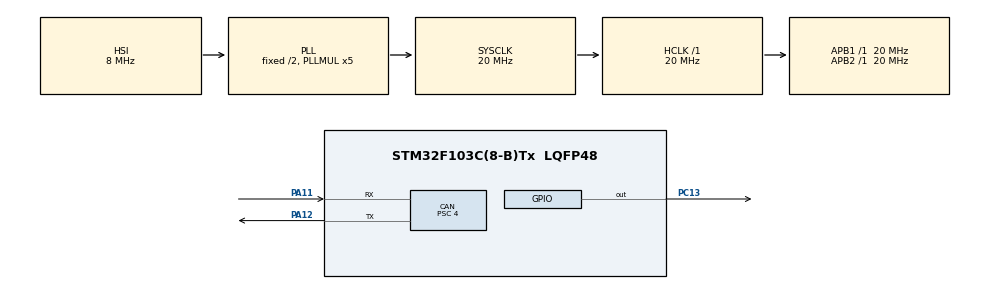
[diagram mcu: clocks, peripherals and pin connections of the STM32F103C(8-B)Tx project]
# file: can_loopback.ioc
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Mcu.Family=STM32F1
PD1-OSC_OUT.Mode=HSE-External-Oscillator
CAN.CalculateBaudRate=500000
PC13-TAMPER-RTC.Signal=GPIO_Output
PA11.Mode=CAN_Activate
PD0-OSC_IN.Signal=RCC_OSC_IN
CAN.CalculateTimeBit=2000.00
RCC.SYSCLKSource=RCC_SYSCLKSOURCE_PLLCLK
ProjectManager.StackSize=0x400
PD1-OSC_OUT.Signal=RCC_OSC_OUT
PA13.Signal=SYS_JTMS-SWDIO
PA12.Signal=CAN_TX
CAN.Prescaler=4
CAN.BS1=CAN_BS1_8TQ
ProjectManager.TargetToolchain=STM32CubeIDE
RCC.HCLKFreq_Value=20000000
RCC.APB2TimFreq_Value=20000000
RCC.USBFreq_Value=20000000
CAN.Mode=CAN_MODE_LOOPBACK
RCC.AHBFreq_Value=20000000
PD0-OSC_IN.Mode=HSE-External-Oscillator
board=custom
RCC.PLLMUL=RCC_PLL_MUL5
RCC.APB2Freq_Value=20000000
PA14.Mode=Serial_Wire
CAN.NART=ENABLE
PA13.Mode=Serial_Wire
Mcu.Name=STM32F103C(8-B)Tx
CAN.CalculateTimeQuantum=200.0
RCC.SYSCLKFreq_VALUE=20000000
Mcu.Package=LQFP48
PA12.Mode=CAN_Activate
RCC.HSEDivPLL=RCC_HSE_PREDIV_DIV2
PA11.Signal=CAN_RX
PA14.Signal=SYS_JTCK-SWCLK
ProjectManager.HeapSize=0x200
NVIC.PriorityGroup=NVIC_PRIORITYGROUP_4
RCC.APB1TimFreq_Value=20000000
RCC.APB1Freq_Value=20000000

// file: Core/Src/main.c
/* USER CODE BEGIN Header */
/**
  ******************************************************************************
  * @file           : main.c
  * @brief          : Main program body
  ******************************************************************************
  * @attention
  *
  * <h2><center>&copy; Copyright (c) 2020 STMicroelectronics.
  * All rights reserved.</center></h2>
  *
  * This software component is licensed by ST under BSD 3-Clause license,
  * the "License"; You may not use this file except in compliance with the
  * License. You may obtain a copy of the License at:
  *                        opensource.org/licenses/BSD-3-Clause
  *
  ******************************************************************************
  */
/* USER CODE END Header */
#include "main.h"

CAN_HandleTypeDef hcan;

/* USER CODE BEGIN PV */
CAN_TxHeaderTypeDef TxHeader;
CAN_RxHeaderTypeDef RxHeader;
CAN_FilterTypeDef sFilterConfig;
uint32_t TxMailbox;
/* USER CODE END PV */

void SystemClock_Config(void);
static void MX_GPIO_Init(void);
static void MX_CAN_Init(void);

int main(void)
{

  /* MCU Configuration--------------------------------------------------------*/

  /* Reset of all peripherals, Initializes the Flash interface and the Systick. */
  HAL_Init();

  /* Configure the system clock */
  SystemClock_Config();

  /* Initialize all configured peripherals */
  MX_GPIO_Init();
  MX_CAN_Init();
  /* USER CODE BEGIN 2 */
  sFilterConfig.FilterFIFOAssignment = CAN_FILTER_FIFO0;
  sFilterConfig.FilterBank = 0;
  sFilterConfig.FilterMode = CAN_FILTERMODE_IDMASK;
  sFilterConfig.FilterScale = CAN_FILTERSCALE_32BIT;
  sFilterConfig.FilterIdHigh = 0x103 << 5;
  sFilterConfig.FilterIdLow = 0;
  sFilterConfig.FilterMaskIdHigh = 0x100 << 5;
  sFilterConfig.FilterMaskIdLow = 0;
  sFilterConfig.FilterFIFOAssignment = CAN_RX_FIFO0;
  sFilterConfig.FilterActivation = ENABLE;
  sFilterConfig.SlaveStartFilterBank = 14;

  TxHeader.DLC = 5;
  TxHeader.StdId = 0x65D;
  TxHeader.IDE = CAN_ID_STD;
  TxHeader.RTR = CAN_RTR_DATA;
  TxHeader.TransmitGlobalTime = DISABLE;

  // Initialize CAN filter
  HAL_CAN_ConfigFilter(&hcan, &sFilterConfig);
  HAL_CAN_Start(&hcan);
  /* USER CODE END 2 */

  /* Infinite loop */
  while (1)
  {

    /* USER CODE BEGIN 3 */
	  uint8_t TxData[5] = {'H', 'E', 'L', 'L', 'O'};
	  HAL_CAN_AddTxMessage(&hcan, &TxHeader, TxData, &TxMailbox);
	  while(HAL_CAN_IsTxMessagePending(&hcan, TxMailbox));

	  HAL_Delay(1000);
  }
  /* USER CODE END 3 */
}

void SystemClock_Config(void)
{
  RCC_OscInitTypeDef RCC_OscInitStruct = {0};
  RCC_ClkInitTypeDef RCC_ClkInitStruct = {0};

  /** Initializes the RCC Oscillators according to the specified parameters
  * in the RCC_OscInitTypeDef structure.
  */
  RCC_OscInitStruct.OscillatorType = RCC_OSCILLATORTYPE_HSI;
  RCC_OscInitStruct.HSIState = RCC_HSI_ON;
  RCC_OscInitStruct.HSICalibrationValue = RCC_HSICALIBRATION_DEFAULT;
  RCC_OscInitStruct.PLL.PLLState = RCC_PLL_ON;
  RCC_OscInitStruct.PLL.PLLSource = RCC_PLLSOURCE_HSI_DIV2;
  RCC_OscInitStruct.PLL.PLLMUL = RCC_PLL_MUL5;
  if (HAL_RCC_OscConfig(&RCC_OscInitStruct) != HAL_OK)
  {
    Error_Handler();
  }
  /** Initializes the CPU, AHB and APB buses clocks
  */
  RCC_ClkInitStruct.ClockType = RCC_CLOCKTYPE_HCLK|RCC_CLOCKTYPE_SYSCLK
                              |RCC_CLOCKTYPE_PCLK1|RCC_CLOCKTYPE_PCLK2;
  RCC_ClkInitStruct.SYSCLKSource = RCC_SYSCLKSOURCE_PLLCLK;
  RCC_ClkInitStruct.AHBCLKDivider = RCC_SYSCLK_DIV1;
  RCC_ClkInitStruct.APB1CLKDivider = RCC_HCLK_DIV1;
  RCC_ClkInitStruct.APB2CLKDivider = RCC_HCLK_DIV1;

  if (HAL_RCC_ClockConfig(&RCC_ClkInitStruct, FLASH_LATENCY_0) != HAL_OK)
  {
    Error_Handler();
  }
}

static void MX_CAN_Init(void)
{

  hcan.Instance = CAN1;
  hcan.Init.Prescaler = 4;
  hcan.Init.Mode = CAN_MODE_LOOPBACK;
  hcan.Init.SyncJumpWidth = CAN_SJW_1TQ;
  hcan.Init.TimeSeg1 = CAN_BS1_8TQ;
  hcan.Init.TimeSeg2 = CAN_BS2_1TQ;
  hcan.Init.TimeTriggeredMode = DISABLE;
  hcan.Init.AutoBusOff = DISABLE;
  hcan.Init.AutoWakeUp = DISABLE;
  hcan.Init.AutoRetransmission = ENABLE;
  hcan.Init.ReceiveFifoLocked = DISABLE;
  hcan.Init.TransmitFifoPriority = DISABLE;
  if (HAL_CAN_Init(&hcan) != HAL_OK)
  {
    Error_Handler();
  }

}

static void MX_GPIO_Init(void)
{
  GPIO_InitTypeDef GPIO_InitStruct = {0};

  /* GPIO Ports Clock Enable */
  __HAL_RCC_GPIOC_CLK_ENABLE();
  __HAL_RCC_GPIOD_CLK_ENABLE();
  __HAL_RCC_GPIOA_CLK_ENABLE();

  /*Configure GPIO pin Output Level */
  HAL_GPIO_WritePin(GPIOC, GPIO_PIN_13, GPIO_PIN_RESET);

  /*Configure GPIO pin : PC13 */
  GPIO_InitStruct.Pin = GPIO_PIN_13;
  GPIO_InitStruct.Mode = GPIO_MODE_OUTPUT_PP;
  GPIO_InitStruct.Pull = GPIO_NOPULL;
  GPIO_InitStruct.Speed = GPIO_SPEED_FREQ_LOW;
  HAL_GPIO_Init(GPIOC, &GPIO_InitStruct);

}

void Error_Handler(void)
{
}

/************************ (C) COPYRIGHT STMicroelectronics *****END OF FILE****/
